# STM32WBA64xx register map
File version: 1.0
Registers are 32-bit, read-write, reset 0x0 unless marked. A register's access mark holds for its fields unless they carry their own. Offsets are from the block's base; [hi:lo] are bit positions; lines under a group give offsets from that group; {n}, {i} and the like mark numbered series.

## RSSLIB_PFUNC — RSSLib function pointer structure
Base 0x0BF97E40
0x28 CloseExitHDP ro — RSSLIB Close and exit HDP

## WWDG
Base 0x40002C00
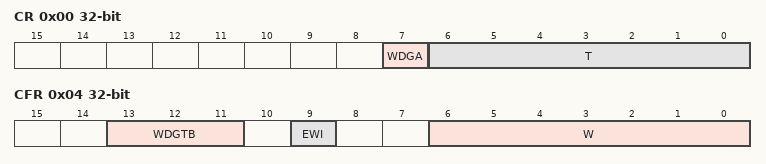
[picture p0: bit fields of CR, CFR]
0x00 CR — WWDG Control register
  [7] WDGA — Activation bit
  [6:0] T — T[6:0] bits (7-Bit counter (MSB to LSB))
0x04 CFR — WWDG Configuration register
  [13:11] WDGTB — WDGTB[2:0] bits (Timer Base)
    0=PRESCALER_1 (WWDG counter clock = (PCLK1/4096)/1); 1=PRESCALER_2 (WWDG counter clock = (PCLK1/4096)/2); 2=PRESCALER_4 (WWDG counter clock = (PCLK1/4096)/4); 3=PRESCALER_8 (WWDG counter clock = (PCLK1/4096)/8); 4=PRESCALER_16 (WWDG counter clock = (PCLK1/4096)/16); 5=PRESCALER_32 (WWDG counter clock = (PCLK1/4096)/32); 6=PRESCALER_64 (WWDG counter clock = (PCLK1/4096)/64); 7=PRESCALER_128 (WWDG counter clock = (PCLK1/4096)/128)
  [9] EWI — Early Wakeup Interrupt
  [6:0] W — W[6:0] bits (7-bit window value)
0x08 SR — WWDG Status register
  [0] EWIF — Early Wakeup Interrupt Flag

## IWDG
Base 0x40003000
0x00 KR — IWDG Key register
  [15:0] KEY — Key value (write only, read 0000h)
0x04 PR — IWDG Prescaler register
  [3:0] PR — PR[3:0] (Prescaler divider)
0x08 RLR — IWDG Reload register
  [11:0] RL — Watchdog counter reload value
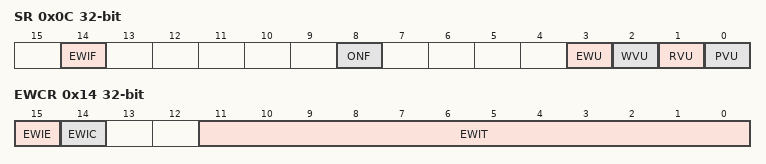
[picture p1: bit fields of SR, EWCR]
0x0C SR — IWDG Status register
  [14] EWIF — Watchdog early interrupt flag
  [8] ONF — Watchdog enable status bit
  [3] EWU — Watchdog interrupt comparator value update
  [2] WVU — Watchdog counter window value update
  [1] RVU — Watchdog counter reload value update
  [0] PVU — Watchdog prescaler value update
0x10 WINR — IWDG Window register
  [11:0] WIN — Watchdog counter window value
0x14 EWCR — IWDG Early Wakeup register
  [15] EWIE — Watchdog early wakeup comparator value
  [14] EWIC — Watchdog early wakeup comparator value
  [11:0] EWIT — Watchdog early wakeup comparator value

## CRC — CRC calculation unit
Base 0x40023000
0x00 DR — CRC Data register
  [31:0] DR — Data register bits
0x04 IDR — CRC Independent data register
  [31:0] IDR — General-purpose 32-bits data register bits
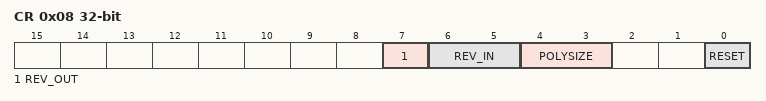
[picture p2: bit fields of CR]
0x08 CR — CRC Control register
  [7] REV_OUT — REV_OUT Reverse Output Data bits
    0=NONE (Output Data bit order not affected); 1=BIT (Output Data bit reversal done by bit)
  [6:5] REV_IN — REV_IN Reverse Input Data bits
    0=NONE (Input Data bit order not affected); 1=BYTE (Input Data bit reversal done by byte); 2=HALFWORD (Input Data bit reversal done by half-word); 3=WORD (Input Data bit reversal done by word)
  [4:3] POLYSIZE — Polynomial size bits
    0=POLYLENGTH_32B (32 bits Polynomial size); 1=POLYLENGTH_16B (16 bits Polynomial size); 2=POLYLENGTH_8B (8 bits Polynomial size); 3=POLYLENGTH_7B (7 bits Polynomial size)
  [0] RESET — RESET the CRC computation unit bit
0x10 INIT — Initial CRC value register
  [31:0] INIT — Initial CRC value bits
0x14 POL — CRC polynomial register
  [31:0] POL — Coefficients of the polynomial

## TSC
Base 0x40024000
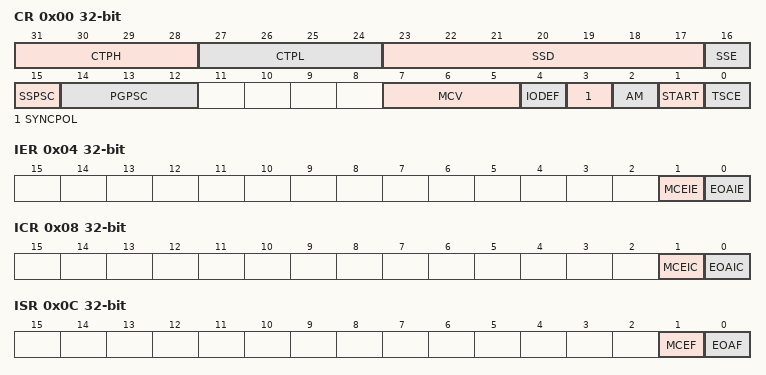
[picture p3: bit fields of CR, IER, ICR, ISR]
0x00 CR — TSC Control register
  [31:28] CTPH — CTPH[3:0] bits (Charge Transfer pulse high)
  [27:24] CTPL — CTPL[3:0] bits (Charge Transfer pulse low)
  [23:17] SSD — SSD[6:0] bits (Spread Spectrum Deviation)
  [16] SSE — Spread Spectrum Enable
  [15] SSPSC — Spread Spectrum Prescaler
  [14:12] PGPSC — PGPSC[2:0] bits (Pulse Generator Prescaler)
  [7:5] MCV — MCV[2:0] bits (Max Count Value)
  [4] IODEF — IO default mode
  [3] SYNCPOL — Synchronization pin polarity
  [2] AM — Acquisition mode
  [1] START — Start acquisition
  [0] TSCE — Touch sensing controller enable
0x04 IER — TSC Interrupt Enable register
  [1] MCEIE — Max count error interrupt enable
  [0] EOAIE — End of acquisition interrupt enable
0x08 ICR — TSC Interrupt Control register
  [1] MCEIC — Max count error interrupt clear
  [0] EOAIC — End of acquisition interrupt clear
0x0C ISR — TSC Interrupt Status register
  [1] MCEF — Max count error flag
  [0] EOAF — End of acquisition flag
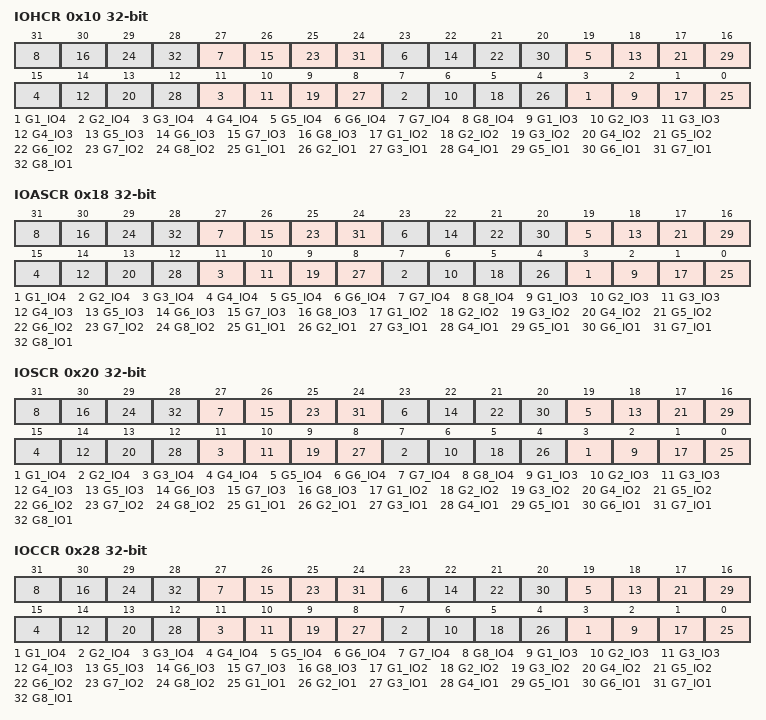
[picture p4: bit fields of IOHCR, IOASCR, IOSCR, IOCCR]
0x10 IOHCR — TSC I/O hysteresis control register
  [4n-1] G{n}_IO4 (n=1..8) — GROUP{n}_IO4 schmitt trigger hysteresis mode
  [4n-2] G{n}_IO3 (n=1..8) — GROUP{n}_IO3 schmitt trigger hysteresis mode
  [4n-3] G{n}_IO2 (n=1..8) — GROUP{n}_IO2 schmitt trigger hysteresis mode
  [4n-4] G{n}_IO1 (n=1..8) — GROUP{n}_IO1 schmitt trigger hysteresis mode
0x18 IOASCR — TSC I/O analog switch control register
  [4n-1] G{n}_IO4 (n=1..8) — GROUP{n}_IO4 analog switch enable
  [4n-2] G{n}_IO3 (n=1..8) — GROUP{n}_IO3 analog switch enable
  [4n-3] G{n}_IO2 (n=1..8) — GROUP{n}_IO2 analog switch enable
  [4n-4] G{n}_IO1 (n=1..8) — GROUP{n}_IO1 analog switch enable
0x20 IOSCR — TSC I/O sampling control register
  [4n-1] G{n}_IO4 (n=1..8) — GROUP{n}_IO4 sampling mode
  [4n-2] G{n}_IO3 (n=1..8) — GROUP{n}_IO3 sampling mode
  [4n-3] G{n}_IO2 (n=1..8) — GROUP{n}_IO2 sampling mode
  [4n-4] G{n}_IO1 (n=1..8) — GROUP{n}_IO1 sampling mode
0x28 IOCCR — TSC I/O channel control register
  [4n-1] G{n}_IO4 (n=1..8) — GROUP{n}_IO4 channel mode
  [4n-2] G{n}_IO3 (n=1..8) — GROUP{n}_IO3 channel mode
  [4n-3] G{n}_IO2 (n=1..8) — GROUP{n}_IO2 channel mode
  [4n-4] G{n}_IO1 (n=1..8) — GROUP{n}_IO1 channel mode
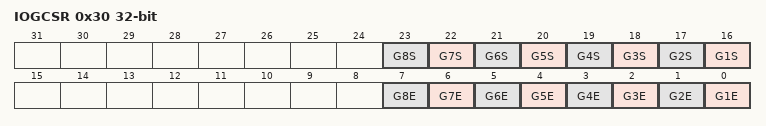
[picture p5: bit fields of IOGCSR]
0x30 IOGCSR — TSC I/O group control status register
  [n+15] G{n}S (n=1..8) — Analog IO GROUP{n} status
  [n-1] G{n}E (n=1..8) — Analog IO GROUP{n} enable
{0x30+4i} IOG{i}CR (i=1..7) — TSC I/O group x counter register
  [13:0] CNT — CNT[13:0] bits (Counter value)
